# STM32L15xxE register map
File version: 1.0
Registers are 32-bit, read-write, reset 0x0 unless marked. A register's access mark holds for its fields unless they carry their own. Offsets are from the block's base; [hi:lo] are bit positions; {n}, {i} and the like mark numbered series.

## LCD — Liquid crystal display controller
Base 0x40002400
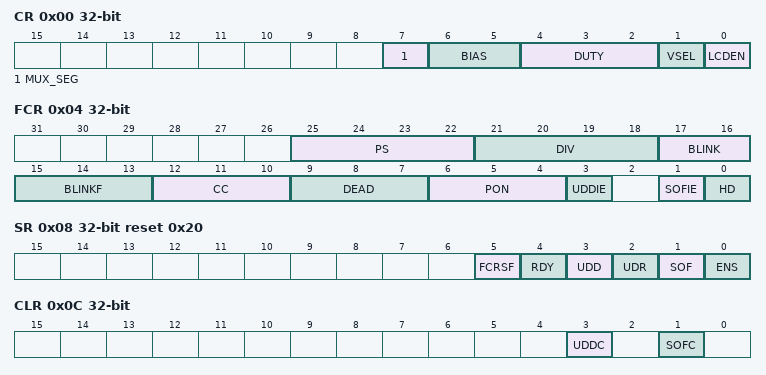
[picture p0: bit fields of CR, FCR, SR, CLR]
0x00 CR — control register
  [7] MUX_SEG — Mux segment enable
  [6:5] BIAS — Bias selector
  [4:2] DUTY — Duty selection
  [1] VSEL — Voltage source selection
  [0] LCDEN — LCD controller enable
0x04 FCR — frame control register
  [25:22] PS — PS 16-bit prescaler
  [21:18] DIV — DIV clock divider
  [17:16] BLINK — Blink mode selection
  [15:13] BLINKF — Blink frequency selection
  [12:10] CC — Contrast control
  [9:7] DEAD — Dead time duration
  [6:4] PON — Pulse ON duration
  [3] UDDIE — Update display done interrupt enable
  [1] SOFIE — Start of frame interrupt enable
  [0] HD — High drive enable
0x08 SR access per field reset 0x20 — status register
  [5] FCRSF ro — LCD Frame Control Register Synchronization flag
  [4] RDY ro — Ready flag
  [3] UDD ro — Update Display Done
  [2] UDR rw — Update display request
  [1] SOF ro — Start of frame flag
  [0] ENS ro — LCD enabled status
0x0C CLR wo — clear register
  [3] UDDC — Update display done clear
  [1] SOFC — Start of frame flag clear
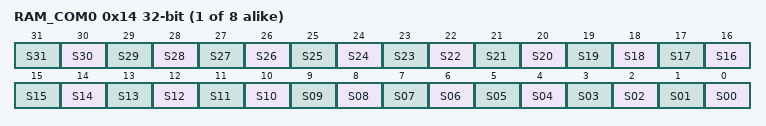
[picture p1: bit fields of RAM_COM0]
{0x14+8i} RAM_COM{i} (i=0..7) — display memory
  [n] S{n:02} (n=0..31)

## PWR — Power control
Base 0x40007000
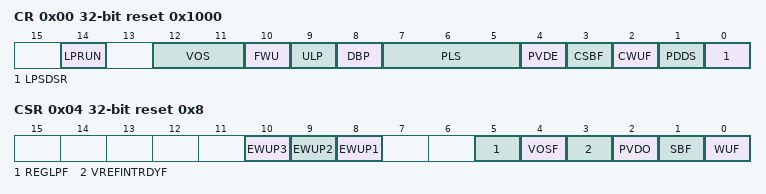
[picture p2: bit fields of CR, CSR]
0x00 CR reset 0x1000 — power control register
  [14] LPRUN — Low power run mode
  [12:11] VOS — Voltage scaling range selection
  [10] FWU — Fast wakeup
  [9] ULP — Ultralow power mode
  [8] DBP — Disable backup domain write protection
  [7:5] PLS — PVD level selection
  [4] PVDE — Power voltage detector enable
  [3] CSBF — Clear standby flag
  [2] CWUF — Clear wakeup flag
  [1] PDDS — Power down deepsleep
  [0] LPSDSR — Low-power deep sleep
0x04 CSR access per field reset 0x8 — power control/status register
  [10] EWUP3 rw — Enable WKUP pin 3
  [9] EWUP2 rw — Enable WKUP pin 2
  [8] EWUP1 rw — Enable WKUP pin 1
  [5] REGLPF ro — Regulator LP flag
  [4] VOSF ro — Voltage Scaling select flag
  [3] VREFINTRDYF ro — Internal voltage reference (VREFINT) ready flag
  [2] PVDO ro — PVD output
  [1] SBF ro — Standby flag
  [0] WUF ro — Wakeup flag

## SYSCFG — System configuration controller
Base 0x40010000
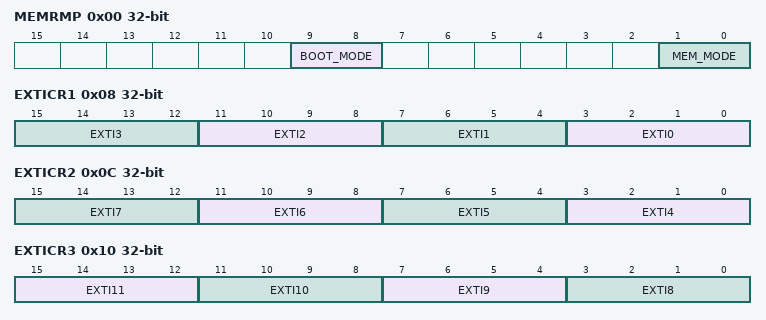
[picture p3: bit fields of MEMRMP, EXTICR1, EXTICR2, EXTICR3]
0x00 MEMRMP access per field — memory remap register
  [9:8] BOOT_MODE ro, [1:0] MEM_MODE rw
0x04 PMC — peripheral mode configuration register
  [0] USB_PU — USB pull-up
0x08 EXTICR1 — external interrupt configuration register 1
  [4n+3:4n] EXTI{n} (n=0..3) — EXTI x configuration (x = 0 to 3)
0x0C EXTICR2 — external interrupt configuration register 2
  [4n-13:4n-16] EXTI{n} (n=4..7) — EXTI x configuration (x = 4 to 7)
0x10 EXTICR3 — external interrupt configuration register 3
  [15:12] EXTI11 — EXTI x configuration (x = 8 to 11)
  [11:8] EXTI10
  [7:4] EXTI9 — EXTI x configuration (x = 8 to 11)
  [3:0] EXTI8 — EXTI x configuration (x = 8 to 11)
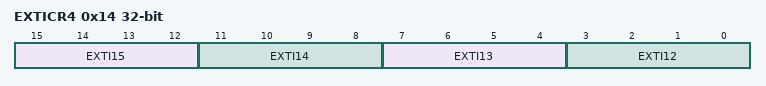
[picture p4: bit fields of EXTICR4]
0x14 EXTICR4 — external interrupt configuration register 4
  [15:12] EXTI15 — EXTI x configuration (x = 12 to 15)
  [11:8] EXTI14
  [7:4] EXTI13
  [3:0] EXTI12

## USB — Universal serial bus full-speed device interface
Base 0x40005C00
Same registers: USB_SRAM 0x40006000
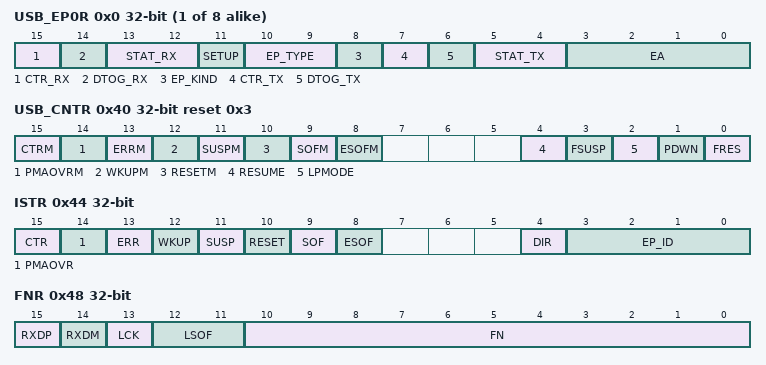
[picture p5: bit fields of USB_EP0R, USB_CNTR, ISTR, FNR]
{0x0+4i} USB_EP{i}R (i=0..7) — endpoint {i} register
  [15] CTR_RX — Correct transfer for reception
  [14] DTOG_RX — Data Toggle, for reception transfers
  [13:12] STAT_RX — Status bits, for reception transfers
  [11] SETUP — Setup transaction completed
  [10:9] EP_TYPE — Endpoint type
  [8] EP_KIND — Endpoint kind
  [7] CTR_TX — Correct Transfer for transmission
  [6] DTOG_TX — Data Toggle, for transmission transfers
  [5:4] STAT_TX — Status bits, for transmission transfers
  [3:0] EA — Endpoint address
0x40 USB_CNTR reset 0x3 — control register
  [15] CTRM — Correct transfer interrupt mask
  [14] PMAOVRM — Packet memory area over / underrun interrupt mask
  [13] ERRM — Error interrupt mask
  [12] WKUPM — Wakeup interrupt mask
  [11] SUSPM — Suspend mode interrupt mask
  [10] RESETM — USB reset interrupt mask
  [9] SOFM — Start of frame interrupt mask
  [8] ESOFM — Expected start of frame interrupt mask
  [4] RESUME — Resume request
  [3] FSUSP — Force suspend
  [2] LPMODE — Low-power mode
  [1] PDWN — Power down
  [0] FRES — Force USB Reset
0x44 ISTR — interrupt status register
  [15] CTR — Correct transfer
  [14] PMAOVR — Packet memory area over / underrun
  [13] ERR — Error
  [12] WKUP — Wakeup
  [11] SUSP — Suspend mode request
  [10] RESET — reset request
  [9] SOF — start of frame
  [8] ESOF — Expected start frame
  [4] DIR — Direction of transaction
  [3:0] EP_ID — Endpoint Identifier
0x48 FNR ro — frame number register
  [15] RXDP — Receive data + line status
  [14] RXDM — Receive data - line status
  [13] LCK — Locked
  [12:11] LSOF — Lost SOF
  [10:0] FN — Frame number
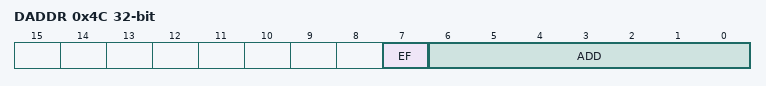
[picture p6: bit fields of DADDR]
0x4C DADDR — device address
  [7] EF — Enable function
  [6:0] ADD — Device address
0x50 BTABLE — Buffer table address
  [15:3] BTABLE — Buffer table
